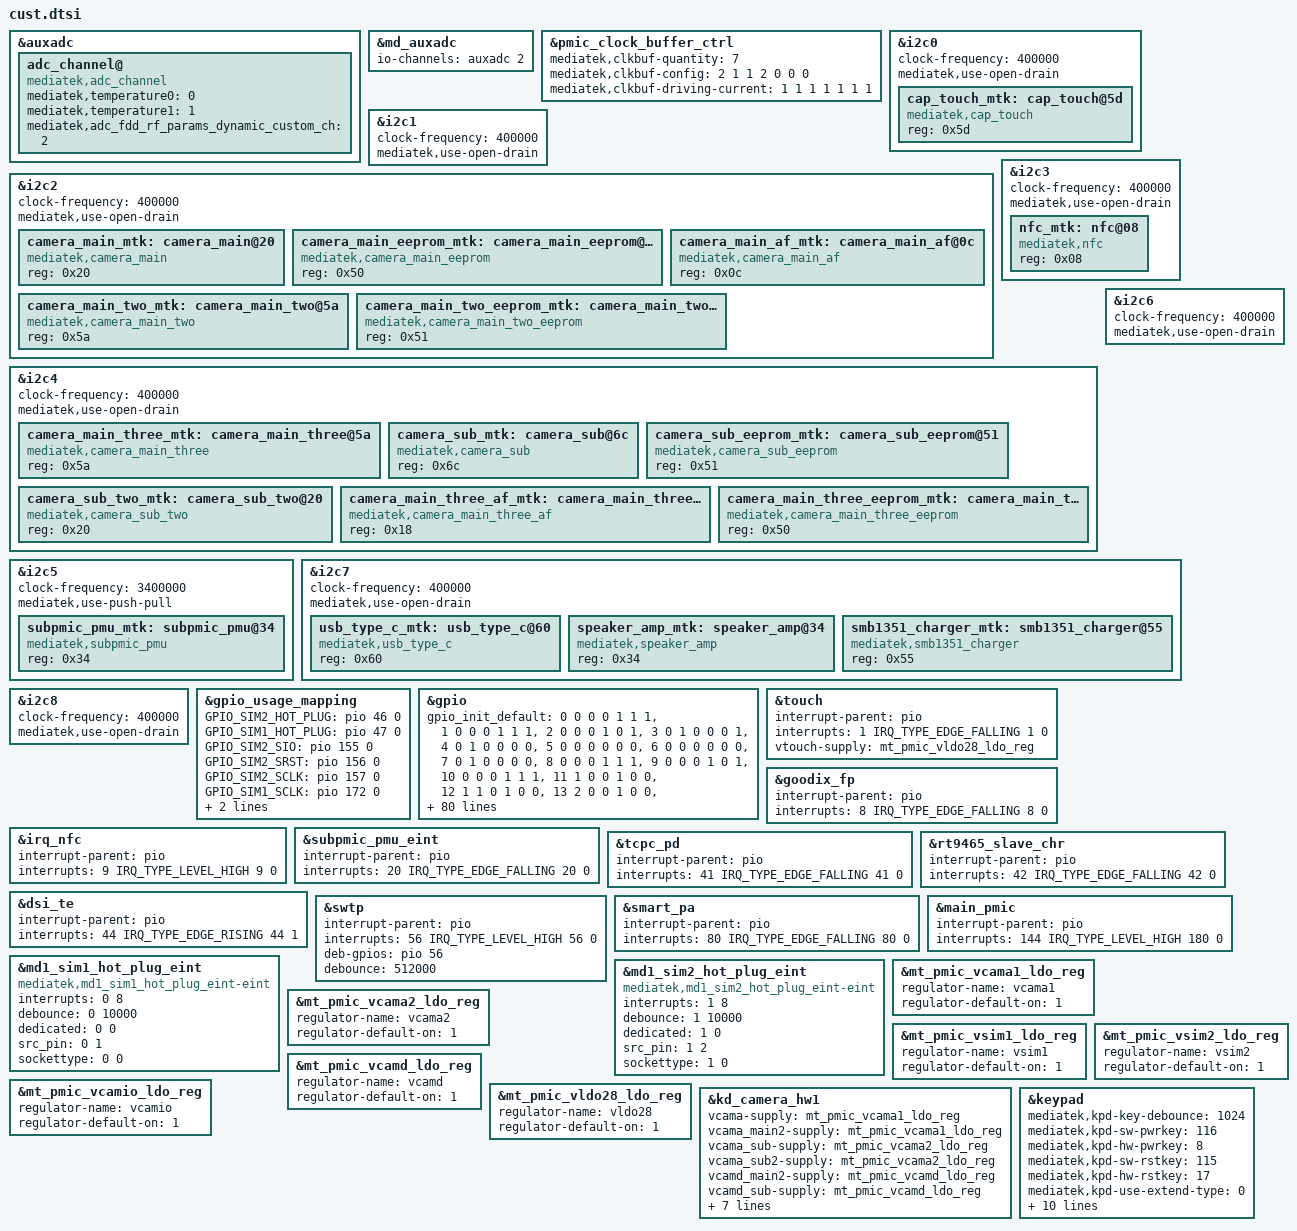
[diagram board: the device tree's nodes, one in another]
/*
 * Generated by MTK SP DrvGen Version: 3.5.160809 for MT6768.
 * 2021-08-01 22:13:43
 * Do Not Modify The File.
 * Copyright Mediatek Inc. (c) 2016.
*/

/*************************
 * ADC DTSI File
*************************/

&auxadc {
	adc_channel@ {
		compatible = "mediatek,adc_channel";
		mediatek,temperature0 = <0>;
		mediatek,temperature1 = <1>;
		mediatek,adc_fdd_rf_params_dynamic_custom_ch = <2>;
		status = "okay";
	};
};
&md_auxadc {
	io-channels = <&auxadc 2>;
};


/*************************
 * CLK_BUF DTSI File
*************************/

&pmic_clock_buffer_ctrl {
	mediatek,clkbuf-quantity = <7>;
	mediatek,clkbuf-config = <2 1 1 2 0 0 0>;
	mediatek,clkbuf-driving-current = <1 1 1 1 1 1 1>;
	status = "okay";
};


/*************************
 * I2C DTSI File
*************************/

&i2c0 {
	#address-cells = <1>;
	#size-cells = <0>;
	clock-frequency = <400000>;
	mediatek,use-open-drain;
	cap_touch_mtk:cap_touch@5d {
		compatible = "mediatek,cap_touch";
		reg = <0x5d>;
		status = "okay";
	};

};

&i2c1 {
	#address-cells = <1>;
	#size-cells = <0>;
	clock-frequency = <400000>;
	mediatek,use-open-drain;
};

&i2c2 {
	#address-cells = <1>;
	#size-cells = <0>;
	clock-frequency = <400000>;
	mediatek,use-open-drain;
	camera_main_mtk:camera_main@20 {
		compatible = "mediatek,camera_main";
		reg = <0x20>;
		status = "okay";
	};

	camera_main_eeprom_mtk:camera_main_eeprom@50 {
		compatible = "mediatek,camera_main_eeprom";
		reg = <0x50>;
		status = "okay";
	};

	camera_main_af_mtk:camera_main_af@0c {
		compatible = "mediatek,camera_main_af";
		reg = <0x0c>;
		status = "okay";
	};

	camera_main_two_mtk:camera_main_two@5a {
		compatible = "mediatek,camera_main_two";
		reg = <0x5a>;
		status = "okay";
	};

	camera_main_two_eeprom_mtk:camera_main_two_eeprom@51 {
		compatible = "mediatek,camera_main_two_eeprom";
		reg = <0x51>;
		status = "okay";
	};

};

&i2c3 {
	#address-cells = <1>;
	#size-cells = <0>;
	clock-frequency = <400000>;
	mediatek,use-open-drain;
	nfc_mtk:nfc@08 {
		compatible = "mediatek,nfc";
		reg = <0x08>;
		status = "okay";
	};

};

&i2c4 {
	#address-cells = <1>;
	#size-cells = <0>;
	clock-frequency = <400000>;
	mediatek,use-open-drain;
	camera_main_three_mtk:camera_main_three@5a {
		compatible = "mediatek,camera_main_three";
		reg = <0x5a>;
		status = "okay";
	};

	camera_sub_mtk:camera_sub@6c {
		compatible = "mediatek,camera_sub";
		reg = <0x6c>;
		status = "okay";
	};

	camera_sub_eeprom_mtk:camera_sub_eeprom@51 {
		compatible = "mediatek,camera_sub_eeprom";
		reg = <0x51>;
		status = "okay";
	};

	camera_sub_two_mtk:camera_sub_two@20 {
		compatible = "mediatek,camera_sub_two";
		reg = <0x20>;
		status = "okay";
	};

	camera_main_three_af_mtk:camera_main_three_af@18 {
		compatible = "mediatek,camera_main_three_af";
		reg = <0x18>;
		status = "okay";
	};

	camera_main_three_eeprom_mtk:camera_main_three_eeprom@50 {
		compatible = "mediatek,camera_main_three_eeprom";
		reg = <0x50>;
		status = "okay";
	};

};

&i2c5 {
	#address-cells = <1>;
	#size-cells = <0>;
	clock-frequency = <3400000>;
	mediatek,use-push-pull;
	subpmic_pmu_mtk:subpmic_pmu@34 {
		compatible = "mediatek,subpmic_pmu";
		reg = <0x34>;
		status = "okay";
	};

};

&i2c6 {
	#address-cells = <1>;
	#size-cells = <0>;
	clock-frequency = <400000>;
	mediatek,use-open-drain;
};

&i2c7 {
	#address-cells = <1>;
	#size-cells = <0>;
	clock-frequency = <400000>;
	mediatek,use-open-drain;
	usb_type_c_mtk:usb_type_c@60 {
		compatible = "mediatek,usb_type_c";
		reg = <0x60>;
		status = "okay";
	};

	speaker_amp_mtk:speaker_amp@34 {
		compatible = "mediatek,speaker_amp";
		reg = <0x34>;
		status = "okay";
	};

	smb1351_charger_mtk:smb1351_charger@55 {
		compatible = "mediatek,smb1351_charger";
		reg = <0x55>;
		status = "okay";
	};

};

&i2c8 {
	#address-cells = <1>;
	#size-cells = <0>;
	clock-frequency = <400000>;
	mediatek,use-open-drain;
};



/*************************
 * GPIO DTSI File
*************************/

&gpio_usage_mapping {
	GPIO_SIM2_HOT_PLUG = <&pio 46 0>;
	GPIO_SIM1_HOT_PLUG = <&pio 47 0>;
	GPIO_SIM2_SIO = <&pio 155 0>;
	GPIO_SIM2_SRST = <&pio 156 0>;
	GPIO_SIM2_SCLK = <&pio 157 0>;
	GPIO_SIM1_SCLK = <&pio 172 0>;
	GPIO_SIM1_SRST = <&pio 173 0>;
	GPIO_SIM1_SIO = <&pio 174 0>;
};

&gpio{
	gpio_init_default = <0 0 0 0 1 1 1>,
		<1 0 0 0 1 1 1>,
		<2 0 0 0 1 0 1>,
		<3 0 1 0 0 0 1>,
		<4 0 1 0 0 0 0>,
		<5 0 0 0 0 0 0>,
		<6 0 0 0 0 0 0>,
		<7 0 1 0 0 0 0>,
		<8 0 0 0 1 1 1>,
		<9 0 0 0 1 0 1>,
		<10 0 0 0 1 1 1>,
		<11 1 0 0 1 0 0>,
		<12 1 1 0 1 0 0>,
		<13 2 0 0 1 0 0>,
		<14 2 1 1 0 0 0>,
		<15 2 1 0 0 0 0>,
		<16 2 1 0 0 0 0>,
		<17 0 1 0 0 0 1>,
		<18 0 0 0 1 1 1>,
		<19 0 0 0 1 1 1>,
		<20 0 0 0 1 1 1>,
		<21 2 0 0 0 0 0>,
		<22 2 1 1 0 0 0>,
		<23 2 1 0 0 0 0>,
		<24 2 1 0 0 0 0>,
		<25 2 1 1 0 0 0>,
		<26 2 1 0 0 0 0>,
		<27 2 1 0 0 0 0>,
		<28 2 0 0 0 0 0>,
		<29 0 1 0 0 0 0>,
		<30 0 1 0 0 0 0>,
		<31 0 1 0 1 0 0>,
		<32 1 0 0 0 0 0>,
		<33 1 1 1 0 0 0>,
		<34 1 1 0 0 0 0>,
		<35 1 1 0 0 0 0>,
		<36 0 1 1 0 0 0>,
		<37 0 1 1 0 0 0>,
		<38 0 1 1 0 0 0>,
		<39 0 0 0 1 1 1>,
		<40 2 0 0 1 0 0>,
		<41 0 0 0 1 1 1>,
		<42 0 0 0 1 1 1>,
		<43 0 1 1 1 1 0>,
		<44 1 0 0 1 0 0>,
		<45 0 1 0 0 0 0>,
		<46 1 0 0 1 1 0>,
		<47 1 0 0 1 1 0>,
		<48 1 0 0 1 1 1>,
		<49 1 0 0 1 1 1>,
		<50 1 0 0 1 1 1>,
		<51 1 0 0 1 1 1>,
		<52 1 0 0 1 0 0>,
		<53 1 0 0 1 0 0>,
		<54 1 0 0 1 0 0>,
		<55 1 0 0 1 0 0>,
		<56 0 0 0 0 0 0>,
		<57 1 0 0 1 0 0>,
		<58 0 0 0 1 0 0>,
		<59 1 0 0 1 0 0>,
		<60 1 0 0 1 0 0>,
		<61 1 0 0 1 0 0>,
		<62 1 0 0 1 0 0>,
		<63 1 0 0 1 0 0>,
		<64 1 0 0 1 0 0>,
		<65 1 0 0 1 0 0>,
		<66 1 0 0 1 0 0>,
		<67 1 0 0 1 0 0>,
		<68 1 0 0 1 0 0>,
		<69 1 0 0 1 0 0>,
		<70 1 0 0 1 0 0>,
		<71 1 0 0 1 0 0>,
		<72 1 0 0 1 0 0>,
		<73 0 1 0 1 0 0>,
		<74 1 0 0 1 0 0>,
		<75 1 0 0 1 0 0>,
		<76 1 0 0 1 0 0>,
		<77 1 0 0 1 0 0>,
		<78 1 0 0 1 0 0>,
		<79 0 1 0 1 0 1>,
		<80 0 0 0 1 1 1>,
		<81 2 0 0 1 1 1>,
		<82 1 0 0 1 1 1>,
		<83 1 0 0 1 1 1>,
		<84 2 0 0 1 1 1>,
		<85 2 0 0 1 0 0>,
		<86 2 1 0 0 0 0>,
		<87 2 1 0 0 0 0>,
		<88 2 1 0 0 0 0>,
		<89 1 0 0 1 1 1>,
		<90 1 0 0 1 1 1>,
		<91 0 1 0 1 0 0>,
		<92 0 1 0 1 0 0>,
		<93 1 0 0 1 1 0>,
		<94 0 1 0 0 0 0>,
		<95 1 0 0 1 1 0>,
		<96 1 1 0 0 0 0>,
		<97 0 1 0 0 0 0>,
		<98 0 1 0 0 0 0>,
		<99 1 1 0 0 0 0>,
		<100 1 1 0 0 0 0>,
		<101 0 1 0 0 0 0>,
		<102 0 1 0 0 0 0>,
		<103 1 0 0 1 1 1>,
		<104 1 0 0 1 1 1>,
		<105 1 0 0 1 1 1>,
		<106 1 0 0 1 1 1>,
		<107 0 1 0 0 0 0>,
		<108 1 1 0 0 0 0>,
		<109 0 1 0 0 0 0>,
		<110 0 1 0 0 0 0>,
		<111 1 1 0 0 0 0>,
		<112 0 1 0 0 0 0>,
		<113 0 0 0 1 0 0>,
		<114 0 0 0 1 0 0>,
		<115 0 0 0 1 0 0>,
		<116 0 0 0 1 0 0>,
		<117 0 0 0 1 0 0>,
		<118 0 0 0 1 0 0>,
		<119 0 0 0 1 0 0>,
		<120 0 0 0 1 0 0>,
		<121 0 0 0 1 0 0>,
		<134 1 0 0 1 0 1>,
		<135 1 1 0 0 0 0>,
		<136 1 1 0 0 0 0>,
		<137 1 1 0 0 0 0>,
		<138 1 1 0 0 0 0>,
		<139 1 1 0 0 0 0>,
		<140 1 0 0 1 0 0>,
		<141 1 0 0 1 0 0>,
		<142 1 0 0 1 0 0>,
		<143 1 0 0 1 0 0>,
		<144 1 0 0 1 0 0>,
		<145 1 1 0 0 0 0>,
		<146 1 1 0 0 0 0>,
		<147 1 1 0 0 0 0>,
		<148 1 1 0 0 0 0>,
		<149 1 1 0 0 0 0>,
		<150 4 0 0 1 1 0>,
		<151 4 1 0 0 0 0>,
		<152 0 1 0 1 0 0>,
		<153 0 1 0 1 0 0>,
		<154 1 1 0 0 0 0>,
		<155 1 0 0 1 1 0>,
		<156 1 1 0 0 0 0>,
		<157 1 1 0 0 0 0>,
		<158 0 0 0 0 0 0>,
		<159 0 1 0 0 0 0>,
		<160 0 1 0 0 0 0>,
		<161 1 0 0 1 1 1>,
		<162 1 0 0 1 1 1>,
		<163 1 0 0 1 1 1>,
		<164 1 0 0 1 1 1>,
		<165 0 1 0 0 0 0>,
		<166 0 1 0 0 0 0>,
		<167 1 0 0 1 0 0>,
		<168 1 0 0 1 0 0>,
		<169 0 1 0 0 0 0>,
		<170 1 0 0 1 1 1>,
		<171 1 1 0 0 0 1>,
		<172 1 1 0 0 0 0>,
		<173 1 1 0 0 0 0>,
		<174 1 0 0 1 1 0>,
		<175 1 0 0 1 1 1>,
		<176 1 0 0 1 1 1>,
		<178 0 1 0 0 0 0>,
		<179 0 1 0 0 0 0>,
		<180 0 0 0 1 0 0>,
		<181 0 0 0 1 0 0>,
		<182 0 0 0 1 0 0>,
		<183 0 0 0 1 0 0>,
		<184 0 0 0 1 0 0>,
		<185 0 0 0 1 0 0>,
		<186 0 0 0 1 0 0>;
};


/*************************
 * EINT DTSI File
*************************/

#include <dt-bindings/interrupt-controller/irq.h>
#include <dt-bindings/interrupt-controller/arm-gic.h>

&touch {
	interrupt-parent = <&pio>;
	interrupts = <1 IRQ_TYPE_EDGE_FALLING 1 0>;
	status = "okay";
};

&goodix_fp {
	interrupt-parent = <&pio>;
	interrupts = <8 IRQ_TYPE_EDGE_FALLING 8 0>;
	status = "okay";
};

&irq_nfc {
	interrupt-parent = <&pio>;
	interrupts = <9 IRQ_TYPE_LEVEL_HIGH 9 0>;
	status = "okay";
};

&subpmic_pmu_eint {
	interrupt-parent = <&pio>;
	interrupts = <20 IRQ_TYPE_EDGE_FALLING 20 0>;
	status = "okay";
};

&tcpc_pd {
	interrupt-parent = <&pio>;
	interrupts = <41 IRQ_TYPE_EDGE_FALLING 41 0>;
	status = "okay";
};

&rt9465_slave_chr {
	interrupt-parent = <&pio>;
	interrupts = <42 IRQ_TYPE_EDGE_FALLING 42 0>;
	status = "okay";
};

&dsi_te {
	interrupt-parent = <&pio>;
	interrupts = <44 IRQ_TYPE_EDGE_RISING 44 1>;
	status = "okay";
};

&swtp {
	interrupt-parent = <&pio>;
	interrupts = <56 IRQ_TYPE_LEVEL_HIGH 56 0>;
	deb-gpios = <&pio 56 0>;
	debounce = <512000>;
	status = "okay";
};

&smart_pa {
	interrupt-parent = <&pio>;
	interrupts = <80 IRQ_TYPE_EDGE_FALLING 80 0>;
	status = "okay";
};

&main_pmic {
	interrupt-parent = <&pio>;
	interrupts = <144 IRQ_TYPE_LEVEL_HIGH 180 0>;
	status = "okay";
};



/*************************
 * MD1_EINT DTSI File
*************************/

&md1_sim1_hot_plug_eint {
	compatible = "mediatek,md1_sim1_hot_plug_eint-eint";
	interrupts = <0 8>;
	debounce = <0 10000>;
	dedicated = <0 0>;
	src_pin = <0 1>;
	sockettype = <0 0>;
	status = "okay";
};

&md1_sim2_hot_plug_eint {
	compatible = "mediatek,md1_sim2_hot_plug_eint-eint";
	interrupts = <1 8>;
	debounce = <1 10000>;
	dedicated = <1 0>;
	src_pin = <1 2>;
	sockettype = <1 0>;
	status = "okay";
};



/*************************
 * PMIC DTSI File
*************************/

&mt_pmic_vcama1_ldo_reg {
	regulator-name = "vcama1";
	regulator-default-on = <1>; /* 0:skip, 1: off, 2:on */
	status = "okay";
};
&mt_pmic_vcama2_ldo_reg {
	regulator-name = "vcama2";
	regulator-default-on = <1>; /* 0:skip, 1: off, 2:on */
	status = "okay";
};
&mt_pmic_vsim1_ldo_reg {
	regulator-name = "vsim1";
	regulator-default-on = <1>; /* 0:skip, 1: off, 2:on */
	status = "okay";
};
&mt_pmic_vsim2_ldo_reg {
	regulator-name = "vsim2";
	regulator-default-on = <1>; /* 0:skip, 1: off, 2:on */
	status = "okay";
};
&mt_pmic_vcamd_ldo_reg {
	regulator-name = "vcamd";
	regulator-default-on = <1>; /* 0:skip, 1: off, 2:on */
	status = "okay";
};
&mt_pmic_vcamio_ldo_reg {
	regulator-name = "vcamio";
	regulator-default-on = <1>; /* 0:skip, 1: off, 2:on */
	status = "okay";
};
&mt_pmic_vldo28_ldo_reg {
	regulator-name = "vldo28";
	regulator-default-on = <1>; /* 0:skip, 1: off, 2:on */
	status = "okay";
};

&kd_camera_hw1 {
	vcama-supply = <&mt_pmic_vcama1_ldo_reg>;
	vcama_main2-supply = <&mt_pmic_vcama1_ldo_reg>;
	vcama_sub-supply = <&mt_pmic_vcama2_ldo_reg>;
	vcama_sub2-supply = <&mt_pmic_vcama2_ldo_reg>;
	vcamd_main2-supply = <&mt_pmic_vcamd_ldo_reg>;
	vcamd_sub-supply = <&mt_pmic_vcamd_ldo_reg>;
	vcamio-supply = <&mt_pmic_vcamio_ldo_reg>;
	vcamio_sub-supply = <&mt_pmic_vcamio_ldo_reg>;
	vcamio_main2-supply = <&mt_pmic_vcamio_ldo_reg>;
	vcamio_sub2-supply = <&mt_pmic_vcamio_ldo_reg>;
	vcamaf-supply = <&mt_pmic_vldo28_ldo_reg>;
	vcamaf_main3-supply = <&mt_pmic_vldo28_ldo_reg>;
	vcamaf_main2-supply = <&mt_pmic_vldo28_ldo_reg>;
	status = "okay";
};

&touch {
	vtouch-supply = <&mt_pmic_vldo28_ldo_reg>;
	status = "okay";
};


/*************************
 * POWER DTSI File
*************************/



/*************************
 * KPD DTSI File
*************************/

&keypad {
	mediatek,kpd-key-debounce = <1024>;
	mediatek,kpd-sw-pwrkey = <116>;
	mediatek,kpd-hw-pwrkey = <8>;
	mediatek,kpd-sw-rstkey  = <115>;
	mediatek,kpd-hw-rstkey = <17>;
	mediatek,kpd-use-extend-type = <0>;
	/*HW Keycode [0~71] -> Linux Keycode*/
	mediatek,kpd-hw-map-num = <72>;
	mediatek,kpd-hw-init-map = <114 0 0 0 0 0 0 0 0 0 0 0 0 0 0 0 0 0 0 0 0 0 0 0 0 0 0 0 0 0 0 0 0 0 0 0 0 0 0 0 0 0 0 0 0 0 0 0 0 0 0 0 0 0 0 0 0 0 0 0 0 0 0 0 0 0 0 0 0 0 0 0 >;
	mediatek,kpd-pwrkey-eint-gpio = <0>;
	mediatek,kpd-pwkey-gpio-din  = <0>;
	mediatek,kpd-hw-dl-key0 = <17>;
	mediatek,kpd-hw-dl-key1 = <0>;
	mediatek,kpd-hw-dl-key2 = <8>;
	mediatek,kpd-hw-recovery-key = <17>;
	mediatek,kpd-hw-factory-key = <0>;
	status = "okay";
};


